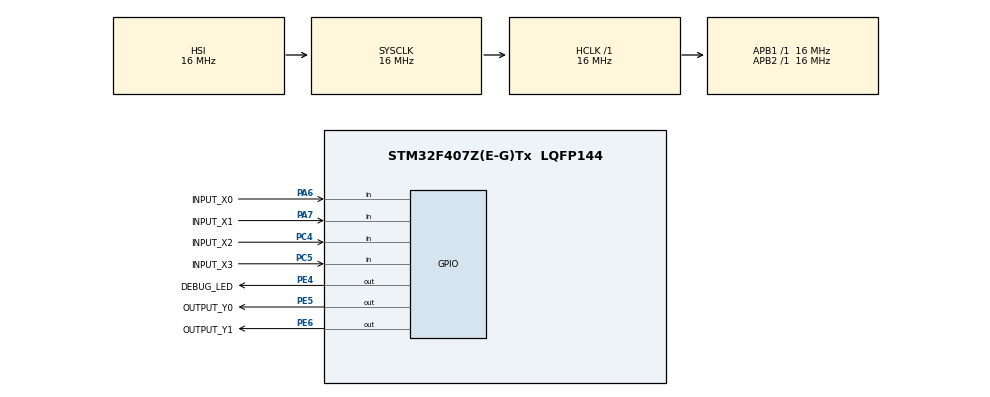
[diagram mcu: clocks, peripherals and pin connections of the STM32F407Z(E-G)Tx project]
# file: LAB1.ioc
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Mcu.Family=STM32F4
Mcu.Name=STM32F407Z(E-G)Tx
Mcu.Package=LQFP144
NVIC.PriorityGroup=NVIC_PRIORITYGROUP_4
PA13.Mode=Serial_Wire
PA13.Signal=SYS_JTMS-SWDIO
PA14.Mode=Serial_Wire
PA14.Signal=SYS_JTCK-SWCLK
PA6.GPIO_Label=INPUT_X0
PA6.Signal=GPIO_Input
PA7.GPIO_Label=INPUT_X1
PA7.Signal=GPIO_Input
PC4.GPIO_Label=INPUT_X2
PC4.Signal=GPIO_Input
PC5.GPIO_Label=INPUT_X3
PC5.Signal=GPIO_Input
PE4.GPIO_Label=DEBUG_LED
PE4.Signal=GPIO_Output
PE5.GPIO_Label=OUTPUT_Y0
PE5.Signal=GPIO_Output
PE6.GPIO_Label=OUTPUT_Y1
PE6.Signal=GPIO_Output
PH0-OSC_IN.Mode=HSE-External-Oscillator
PH0-OSC_IN.Signal=RCC_OSC_IN
PH1-OSC_OUT.Mode=HSE-External-Oscillator
PH1-OSC_OUT.Signal=RCC_OSC_OUT
ProjectManager.HeapSize=0x200
ProjectManager.StackSize=0x400
ProjectManager.TargetToolchain=STM32CubeIDE
RCC.AHBFreq_Value=16000000
RCC.APB1Freq_Value=16000000
RCC.APB2Freq_Value=16000000
RCC.CortexFreq_Value=16000000
RCC.HSE_VALUE=8000000
RCC.HSI_VALUE=16000000
RCC.LSE_VALUE=32768
RCC.SYSCLKFreq_VALUE=16000000
RCC.VCOOutputFreq_Value=192000000
board=custom

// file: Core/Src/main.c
/* USER CODE BEGIN Header */
/**
  ******************************************************************************
  * @file           : main.c
  * @brief          : Main program body
  ******************************************************************************
  * @attention
  *
  * Copyright (c) 2023 STMicroelectronics.
  * All rights reserved.
  *
  * This software is licensed under terms that can be found in the LICENSE file
  * in the root directory of this software component.
  * If no LICENSE file comes with this software, it is provided AS-IS.
  *
  ******************************************************************************
  */
/* USER CODE END Header */
#include "main.h"

/* USER CODE BEGIN PV */
enum state{
	INIT,
	YELLOW,
	GREEN,
	RED
};
/* USER CODE END PV */

void SystemClock_Config(void);
static void MX_GPIO_Init(void);

int main(void)
{

  /* MCU Configuration--------------------------------------------------------*/

  /* Reset of all peripherals, Initializes the Flash interface and the Systick. */
  HAL_Init();

  /* Configure the system clock */
  SystemClock_Config();

  /* Initialize all configured peripherals */
  MX_GPIO_Init();

  /* Infinite loop */
  /* USER CODE BEGIN WHILE */
//  while (1)
//  {
//		 HAL_GPIO_WritePin ( GPIOE , GPIO_PIN_6, 1) ;
//		 HAL_GPIO_WritePin ( GPIOE , GPIO_PIN_5,1) ;
//		 HAL_Delay (2000) ;
//		 HAL_GPIO_WritePin ( GPIOE , GPIO_PIN_6, 0) ;
//		 HAL_GPIO_WritePin ( GPIOE , GPIO_PIN_5,0);
//		 HAL_Delay (4000) ;
//    /* USER CODE BEGIN 3 */
//  }
  /* USER CODE BEGIN WHILE */
  int count = 5;
  state State = INIT;
  while (1)
  {
  /* USER CODE END WHILE */
  	 switch(state){
  	 case INIT:
  		 HAL_GPIO_WritePin ( DEBUG_LED_GPIO_Port , DEBUG_LED_Pin , 0) ;
  		 HAL_GPIO_WritePin ( DEBUG_LED_GPIO_Port , OUTPUT_Y1_Pin , 0) ;
  		 HAL_GPIO_WritePin ( DEBUG_LED_GPIO_Port , OUTPUT_Y0_Pin , 0) ;
  		 state = RED;
  		 break;
  	 case RED:
  		 HAL_GPIO_WritePin ( DEBUG_LED_GPIO_Port , DEBUG_LED_Pin , 1) ;
  		 HAL_GPIO_WritePin ( DEBUG_LED_GPIO_Port , OUTPUT_Y1_Pin , 0) ;
  		 HAL_GPIO_WritePin ( DEBUG_LED_GPIO_Port , OUTPUT_Y0_Pin , 0) ;
  		 if(count<0) {
  			 count = 3;
  			 state = YELLOW;
  		 }
  		 break;

  	 case YELLOW:
  		 HAL_GPIO_WritePin ( DEBUG_LED_GPIO_Port , DEBUG_LED_Pin , 0) ;
  		 HAL_GPIO_WritePin ( DEBUG_LED_GPIO_Port , OUTPUT_Y1_Pin , 1) ;
  		 HAL_GPIO_WritePin ( DEBUG_LED_GPIO_Port , OUTPUT_Y0_Pin , 0) ;
  		 if(count<0) {
  			 count = 1;
  			 state = GREEN;
  		 }
  		 break;

  	 case GREEN:
  		 HAL_GPIO_WritePin ( DEBUG_LED_GPIO_Port , DEBUG_LED_Pin , 0) ;
  		 HAL_GPIO_WritePin ( DEBUG_LED_GPIO_Port , OUTPUT_Y1_Pin , 0) ;
  		 HAL_GPIO_WritePin ( DEBUG_LED_GPIO_Port , OUTPUT_Y0_Pin , 1) ;
  		 if(count<0) {
  			 count = 5;
  			 state = RED;
  		 }
  		 break;
  	 }
  	 count--;
  	 HAL_Delay (1000) ;
  }

  /* USER CODE END 3 */
}

void SystemClock_Config(void)
{
  RCC_OscInitTypeDef RCC_OscInitStruct = {0};
  RCC_ClkInitTypeDef RCC_ClkInitStruct = {0};

  /** Configure the main internal regulator output voltage
  */
  __HAL_RCC_PWR_CLK_ENABLE();
  __HAL_PWR_VOLTAGESCALING_CONFIG(PWR_REGULATOR_VOLTAGE_SCALE1);

  /** Initializes the RCC Oscillators according to the specified parameters
  * in the RCC_OscInitTypeDef structure.
  */
  RCC_OscInitStruct.OscillatorType = RCC_OSCILLATORTYPE_HSI;
  RCC_OscInitStruct.HSIState = RCC_HSI_ON;
  RCC_OscInitStruct.HSICalibrationValue = RCC_HSICALIBRATION_DEFAULT;
  RCC_OscInitStruct.PLL.PLLState = RCC_PLL_NONE;
  if (HAL_RCC_OscConfig(&RCC_OscInitStruct) != HAL_OK)
  {
    Error_Handler();
  }

  /** Initializes the CPU, AHB and APB buses clocks
  */
  RCC_ClkInitStruct.ClockType = RCC_CLOCKTYPE_HCLK|RCC_CLOCKTYPE_SYSCLK
                              |RCC_CLOCKTYPE_PCLK1|RCC_CLOCKTYPE_PCLK2;
  RCC_ClkInitStruct.SYSCLKSource = RCC_SYSCLKSOURCE_HSI;
  RCC_ClkInitStruct.AHBCLKDivider = RCC_SYSCLK_DIV1;
  RCC_ClkInitStruct.APB1CLKDivider = RCC_HCLK_DIV1;
  RCC_ClkInitStruct.APB2CLKDivider = RCC_HCLK_DIV1;

  if (HAL_RCC_ClockConfig(&RCC_ClkInitStruct, FLASH_LATENCY_0) != HAL_OK)
  {
    Error_Handler();
  }
}

static void MX_GPIO_Init(void)
{
  GPIO_InitTypeDef GPIO_InitStruct = {0};

  /* GPIO Ports Clock Enable */
  __HAL_RCC_GPIOE_CLK_ENABLE();
  __HAL_RCC_GPIOH_CLK_ENABLE();
  __HAL_RCC_GPIOA_CLK_ENABLE();
  __HAL_RCC_GPIOC_CLK_ENABLE();

  /*Configure GPIO pin Output Level */
  HAL_GPIO_WritePin(GPIOE, DEBUG_LED_Pin|OUTPUT_Y0_Pin|OUTPUT_Y1_Pin, GPIO_PIN_RESET);

  /*Configure GPIO pins : DEBUG_LED_Pin OUTPUT_Y0_Pin OUTPUT_Y1_Pin */
  GPIO_InitStruct.Pin = DEBUG_LED_Pin|OUTPUT_Y0_Pin|OUTPUT_Y1_Pin;
  GPIO_InitStruct.Mode = GPIO_MODE_OUTPUT_PP;
  GPIO_InitStruct.Pull = GPIO_NOPULL;
  GPIO_InitStruct.Speed = GPIO_SPEED_FREQ_LOW;
  HAL_GPIO_Init(GPIOE, &GPIO_InitStruct);

  /*Configure GPIO pins : INPUT_X0_Pin INPUT_X1_Pin */
  GPIO_InitStruct.Pin = INPUT_X0_Pin|INPUT_X1_Pin;
  GPIO_InitStruct.Mode = GPIO_MODE_INPUT;
  GPIO_InitStruct.Pull = GPIO_NOPULL;
  HAL_GPIO_Init(GPIOA, &GPIO_InitStruct);

  /*Configure GPIO pins : INPUT_X2_Pin INPUT_X3_Pin */
  GPIO_InitStruct.Pin = INPUT_X2_Pin|INPUT_X3_Pin;
  GPIO_InitStruct.Mode = GPIO_MODE_INPUT;
  GPIO_InitStruct.Pull = GPIO_NOPULL;
  HAL_GPIO_Init(GPIOC, &GPIO_InitStruct);

}

void Error_Handler(void)
{
  __disable_irq();
  while (1)
  {
  }
}
